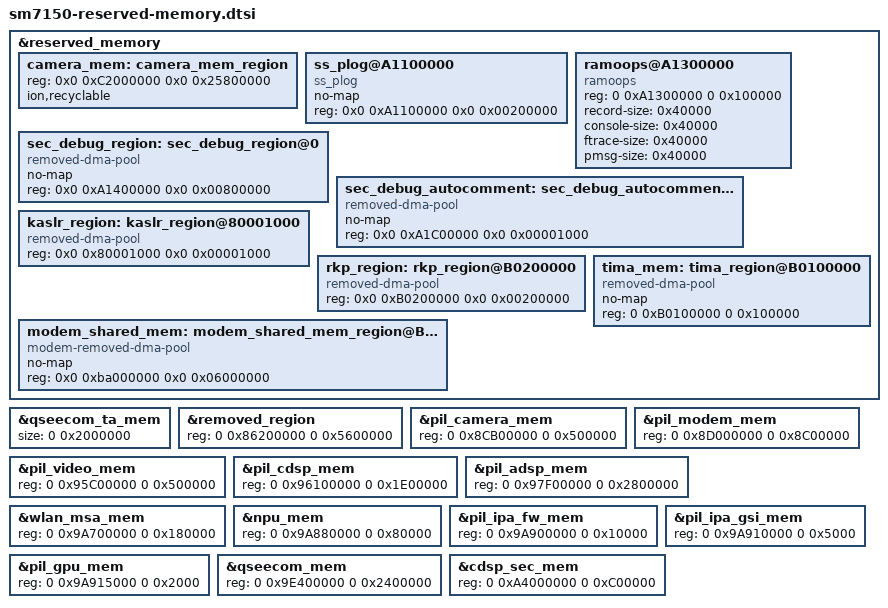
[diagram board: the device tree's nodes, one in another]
&reserved_memory {
	camera_mem: camera_mem_region {
		reg = <0x0 0xC2000000 0x0 0x25800000>;
		ion,recyclable;
	};
    
    ss_plog@A1100000 {
		compatible = "ss_plog";
		no-map;
		reg = <0x0 0xA1100000 0x0 0x00200000>;
	};

	ramoops@A1300000 {
		compatible = "ramoops";
		reg = <0 0xA1300000 0 0x100000>;
		record-size = <0x40000>;
		console-size = <0x40000>;
		ftrace-size = <0x40000>;
		pmsg-size = <0x40000>;
	};

	/* CONFIG_SEC_DEBUG reserves 8MB */
	sec_debug_region: sec_debug_region@0 {
		compatible = "removed-dma-pool";
		no-map;
		reg = <0x0 0xA1400000 0x0 0x00800000>;
	};

	/* sec_debug_low_region reserves 4MB
	   This region is reserved if only debuglevel low */
	/* FIXME:
	sec_debug_low_region: sec_debug_low_region@0 {
		compatible = "removed-dma-pool";
		no-map;
		reg = <0x0 0xA1400000 0x0 0x00400000>;
	};
	*/

	sec_debug_autocomment: sec_debug_autocomment@0 {
		compatible = "removed-dma-pool";
		no-map;
		reg = <0x0 0xA1C00000 0x0 0x00001000>;
	};

	/* Kaslr offset reserve */
	kaslr_region: kaslr_region@80001000 {
		compatible = "removed-dma-pool";
		reg = <0x0 0x80001000 0x0 0x00001000>;
	};

	/* rkp_region reserves 2MB for UH_LOG and UH_STATIC_HEAP */
	/* CAUSION: DO NOT reserve 0xB0200000 ~ 0xB1800000 region for RKP at the runtime */
	rkp_region: rkp_region@B0200000 {
		compatible = "removed-dma-pool";
		reg = <0x0 0xB0200000 0x0 0x00200000>;
	};

	/*to reserve 1MB for TIMA */
	tima_mem: tima_region@B0100000 {
		compatible = "removed-dma-pool";
		no-map;
		reg = <0 0xB0100000 0 0x100000>;
	};

	modem_shared_mem: modem_shared_mem_region@BA000000 {
		compatible = "modem-removed-dma-pool";
		no-map;
		reg = <0x0 0xba000000 0x0 0x06000000>;
	};
};

&qseecom_ta_mem {
	size = <0 0x2000000>;
};

&removed_region {
	reg = <0 0x86200000 0 0x5600000>;
};

&pil_camera_mem{
	reg = <0 0x8CB00000 0 0x500000>;
};

&pil_modem_mem {
	reg = <0 0x8D000000 0 0x8C00000>;
};

&pil_video_mem {
	reg = <0 0x95C00000 0 0x500000>;
};

&pil_cdsp_mem {
	reg = <0 0x96100000 0 0x1E00000>;
};

&pil_adsp_mem {
	reg = <0 0x97F00000 0 0x2800000>;
};

&wlan_msa_mem {
	reg = <0 0x9A700000 0 0x180000>;
};

&npu_mem {
	reg = <0 0x9A880000 0 0x80000>;
};

&pil_ipa_fw_mem {
	reg = <0 0x9A900000 0 0x10000>;
};

&pil_ipa_gsi_mem {
	reg = <0 0x9A910000 0 0x5000>;
};

&pil_gpu_mem {
	reg = <0 0x9A915000 0 0x2000>;
};

&qseecom_mem {
	reg = <0 0x9E400000 0 0x2400000>;
};

&cdsp_sec_mem {
	reg = <0 0xA4000000 0 0xC00000>;
};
